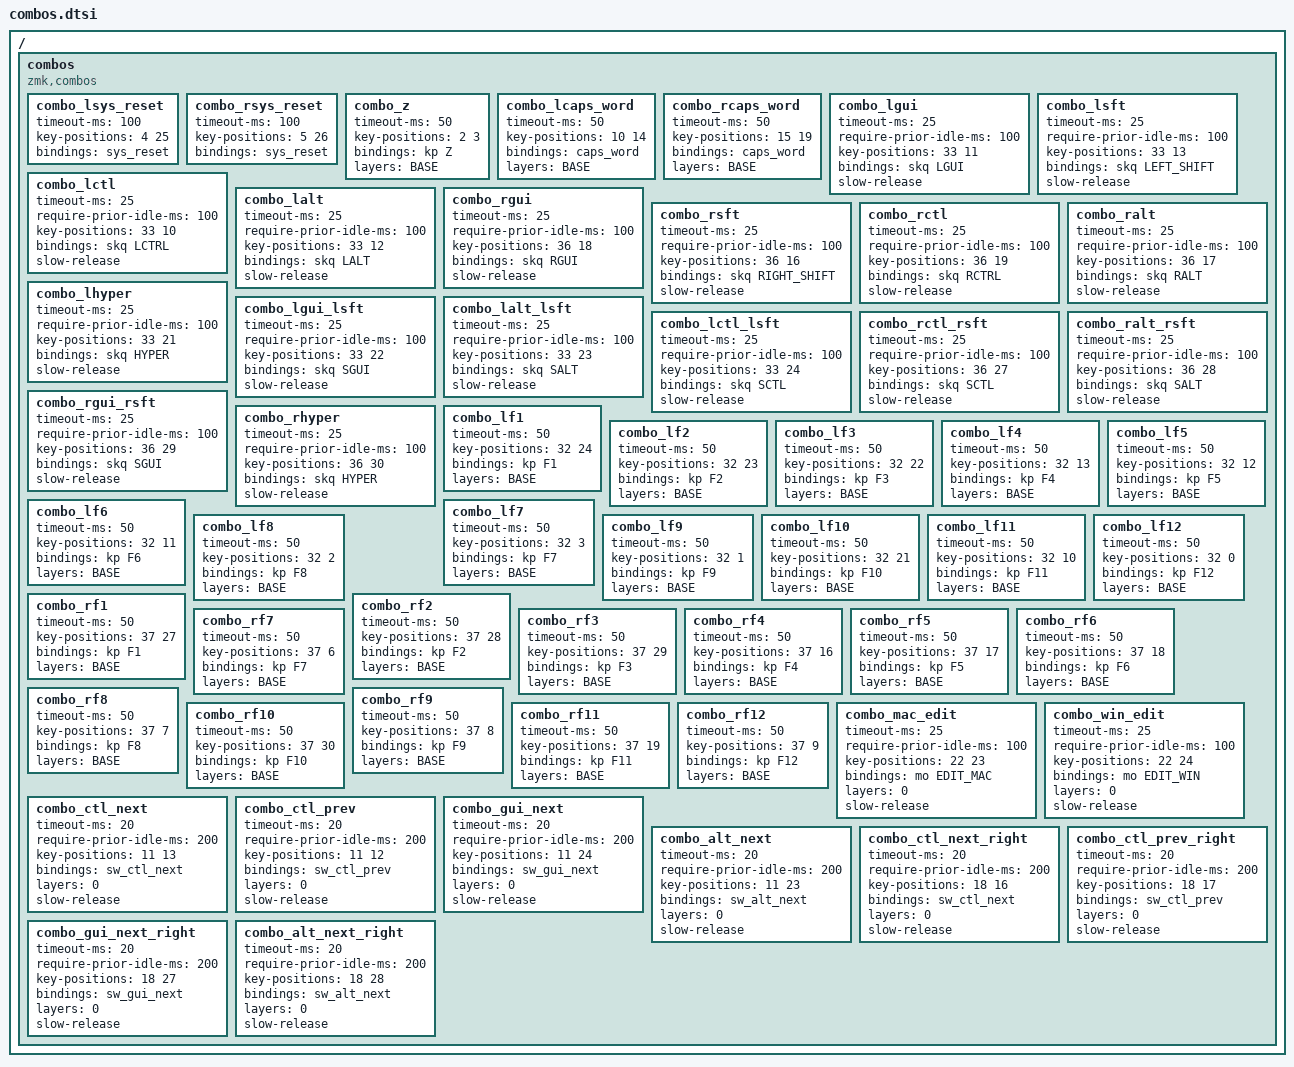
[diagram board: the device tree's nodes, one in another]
/ {
    combos {
        compatible = "zmk,combos";

        /*
        combo_escape {
            timeout-ms = <50>;
            key-positions = <0 1>;
            bindings = <&kp ESC>;
            layers = <0>;
        };
        */
        combo_lsys_reset {
            timeout-ms = <100>;
            key-positions = <4 25>;
            bindings = <&sys_reset>;
        };

        combo_rsys_reset {
            timeout-ms = <100>;
            key-positions = <5 26>;
            bindings = <&sys_reset>;
        };

        combo_z {
            timeout-ms = <50>;
            key-positions = <2 3>;
            bindings = <&kp Z>;
            layers = <BASE>;
        };

        combo_lcaps_word {
            timeout-ms = <50>;
            key-positions = <10 14>;
            bindings = <&caps_word>;
            layers = <BASE>;
        };

        combo_rcaps_word {
            timeout-ms = <50>;
            key-positions = <15 19>;
            bindings = <&caps_word>;
            layers = <BASE>;
        };

        // MODIFIERS
        combo_lgui {
            timeout-ms = <25>;
            require-prior-idle-ms = <100>;
            key-positions = <33 11>;
            bindings = <&skq LGUI>;
            slow-release;
        };

        combo_lsft {
            timeout-ms = <25>;
            require-prior-idle-ms = <100>;
            key-positions = <33 13>;
            bindings = <&skq LEFT_SHIFT>;
            slow-release;
        };

        combo_lctl {
            timeout-ms = <25>;
            require-prior-idle-ms = <100>;
            key-positions = <33 10>;
            bindings = <&skq LCTRL>;
            slow-release;
        };

        combo_lalt {
            timeout-ms = <25>;
            require-prior-idle-ms = <100>;
            key-positions = <33 12>;
            bindings = <&skq LALT>;
            slow-release;
        };

        combo_rgui {
            timeout-ms = <25>;
            require-prior-idle-ms = <100>;
            key-positions = <36 18>;
            bindings = <&skq RGUI>;
            slow-release;
        };

        combo_rsft {
            timeout-ms = <25>;
            require-prior-idle-ms = <100>;
            key-positions = <36 16>;
            bindings = <&skq RIGHT_SHIFT>;
            slow-release;
        };

        combo_rctl {
            timeout-ms = <25>;
            require-prior-idle-ms = <100>;
            key-positions = <36 19>;
            bindings = <&skq RCTRL>;
            slow-release;
        };

        combo_ralt {
            timeout-ms = <25>;
            require-prior-idle-ms = <100>;
            key-positions = <36 17>;
            bindings = <&skq RALT>;
            slow-release;
        };

        combo_lhyper {
            timeout-ms = <25>;
            require-prior-idle-ms = <100>;
            key-positions = <33 21>;
            bindings = <&skq HYPER>;
            slow-release;
        };

        combo_lgui_lsft {
            timeout-ms = <25>;
            require-prior-idle-ms = <100>;
            key-positions = <33 22>;
            bindings = <&skq SGUI>;
            slow-release;
        };

        combo_lalt_lsft {
            timeout-ms = <25>;
            require-prior-idle-ms = <100>;
            key-positions = <33 23>;
            bindings = <&skq SALT>;
            slow-release;
        };

        combo_lctl_lsft {
            timeout-ms = <25>;
            require-prior-idle-ms = <100>;
            key-positions = <33 24>;
            bindings = <&skq SCTL>;
            slow-release;
        };

        combo_rctl_rsft {
            timeout-ms = <25>;
            require-prior-idle-ms = <100>;
            key-positions = <36 27>;
            bindings = <&skq SCTL>;
            slow-release;
        };

        combo_ralt_rsft {
            timeout-ms = <25>;
            require-prior-idle-ms = <100>;
            key-positions = <36 28>;
            bindings = <&skq SALT>;
            slow-release;
        };

        combo_rgui_rsft {
            timeout-ms = <25>;
            require-prior-idle-ms = <100>;
            key-positions = <36 29>;
            bindings = <&skq SGUI>;
            slow-release;
        };

        combo_rhyper {
            timeout-ms = <25>;
            require-prior-idle-ms = <100>;
            key-positions = <36 30>;
            bindings = <&skq HYPER>;
            slow-release;
        };

        // FUNCTION KEYS
        // LEFT
        combo_lf1 {
            timeout-ms = <50>;
            key-positions = <32 24>;
            bindings = <&kp F1>;
            layers = <BASE>;
        };
        combo_lf2 {
            timeout-ms = <50>;
            key-positions = <32 23>;
            bindings = <&kp F2>;
            layers = <BASE>;
        };
        combo_lf3 {
            timeout-ms = <50>;
            key-positions = <32 22>;
            bindings = <&kp F3>;
            layers = <BASE>;
        };
        combo_lf4 {
            timeout-ms = <50>;
            key-positions = <32 13>;
            bindings = <&kp F4>;
            layers = <BASE>;
        };
        combo_lf5 {
            timeout-ms = <50>;
            key-positions = <32 12>;
            bindings = <&kp F5>;
            layers = <BASE>;
        };
        combo_lf6 {
            timeout-ms = <50>;
            key-positions = <32 11>;
            bindings = <&kp F6>;
            layers = <BASE>;
        };
        combo_lf7 {
            timeout-ms = <50>;
            key-positions = <32 3>;
            bindings = <&kp F7>;
            layers = <BASE>;
        };
        combo_lf8 {
            timeout-ms = <50>;
            key-positions = <32 2>;
            bindings = <&kp F8>;
            layers = <BASE>;
        };
        combo_lf9 {
            timeout-ms = <50>;
            key-positions = <32 1>;
            bindings = <&kp F9>;
            layers = <BASE>;
        };
        combo_lf10 {
            timeout-ms = <50>;
            key-positions = <32 21>;
            bindings = <&kp F10>;
            layers = <BASE>;
        };
        combo_lf11 {
            timeout-ms = <50>;
            key-positions = <32 10>;
            bindings = <&kp F11>;
            layers = <BASE>;
        };
        combo_lf12 {
            timeout-ms = <50>;
            key-positions = <32 0>;
            bindings = <&kp F12>;
            layers = <BASE>;
        };

        // RIGHT
        combo_rf1 {
            timeout-ms = <50>;
            key-positions = <37 27>;
            bindings = <&kp F1>;
            layers = <BASE>;
        };
        combo_rf2 {
            timeout-ms = <50>;
            key-positions = <37 28>;
            bindings = <&kp F2>;
            layers = <BASE>;
        };
        combo_rf3 {
            timeout-ms = <50>;
            key-positions = <37 29>;
            bindings = <&kp F3>;
            layers = <BASE>;
        };
        combo_rf4 {
            timeout-ms = <50>;
            key-positions = <37 16>;
            bindings = <&kp F4>;
            layers = <BASE>;
        };
        combo_rf5 {
            timeout-ms = <50>;
            key-positions = <37 17>;
            bindings = <&kp F5>;
            layers = <BASE>;
        };
        combo_rf6 {
            timeout-ms = <50>;
            key-positions = <37 18>;
            bindings = <&kp F6>;
            layers = <BASE>;
        };
        combo_rf7 {
            timeout-ms = <50>;
            key-positions = <37 6>;
            bindings = <&kp F7>;
            layers = <BASE>;
        };
        combo_rf8 {
            timeout-ms = <50>;
            key-positions = <37 7>;
            bindings = <&kp F8>;
            layers = <BASE>;
        };
        combo_rf9 {
            timeout-ms = <50>;
            key-positions = <37 8>;
            bindings = <&kp F9>;
            layers = <BASE>;
        };
        combo_rf10 {
            timeout-ms = <50>;
            key-positions = <37 30>;
            bindings = <&kp F10>;
            layers = <BASE>;
        };
        combo_rf11 {
            timeout-ms = <50>;
            key-positions = <37 19>;
            bindings = <&kp F11>;
            layers = <BASE>;
        };
        combo_rf12 {
            timeout-ms = <50>;
            key-positions = <37 9>;
            bindings = <&kp F12>;
            layers = <BASE>;
        };

        // SWITCHING
        combo_mac_edit {
            timeout-ms = <25>;
            require-prior-idle-ms = <100>;
            key-positions = <22 23>;
            bindings = <&mo EDIT_MAC>;
            layers = <0>;
            slow-release;
        };

        combo_win_edit {
            timeout-ms = <25>;
            require-prior-idle-ms = <100>;
            key-positions = <22 24>;
            bindings = <&mo EDIT_WIN>;
            layers = <0>;
            slow-release;
        };

        combo_ctl_next {
            timeout-ms = <20>;
            require-prior-idle-ms = <200>;
            key-positions = <11 13>;
            bindings = <&sw_ctl_next>;
            layers = <0>;
            slow-release;
        };

        combo_ctl_prev {
            timeout-ms = <20>;
            require-prior-idle-ms = <200>;
            key-positions = <11 12>;
            bindings = <&sw_ctl_prev>;
            layers = <0>;
            slow-release;
        };

        combo_gui_next {
            timeout-ms = <20>;
            require-prior-idle-ms = <200>;
            key-positions = <11 24>;
            bindings = <&sw_gui_next>;
            layers = <0>;
            slow-release;
        };

        combo_alt_next {
            timeout-ms = <20>;
            require-prior-idle-ms = <200>;
            key-positions = <11 23>;
            bindings = <&sw_alt_next>;
            layers = <0>;
            slow-release;
        };

        combo_ctl_next_right {
            timeout-ms = <20>;
            require-prior-idle-ms = <200>;
            key-positions = <18 16>;
            bindings = <&sw_ctl_next>;
            layers = <0>;
            slow-release;
        };

        combo_ctl_prev_right {
            timeout-ms = <20>;
            require-prior-idle-ms = <200>;
            key-positions = <18 17>;
            bindings = <&sw_ctl_prev>;
            layers = <0>;
            slow-release;
        };

        combo_gui_next_right {
            timeout-ms = <20>;
            require-prior-idle-ms = <200>;
            key-positions = <18 27>;
            bindings = <&sw_gui_next>;
            layers = <0>;
            slow-release;
        };

        combo_alt_next_right {
            timeout-ms = <20>;
            require-prior-idle-ms = <200>;
            key-positions = <18 28>;
            bindings = <&sw_alt_next>;
            layers = <0>;
            slow-release;
        };

    };
};
